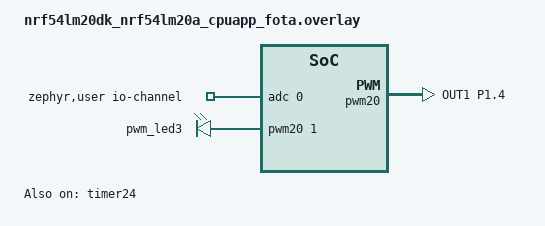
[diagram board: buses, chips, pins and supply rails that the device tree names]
/*
 * Copyright (c) 2026 Nordic Semiconductor ASA
 *
 * SPDX-License-Identifier: LicenseRef-Nordic-5-Clause
 */

#include <nrf54lm20_cpuapp_partitions.dtsi>
#include <ext_flash/nrf54lm20dk_cpuapp_partitions.dtsi>

/ {
	zephyr,user {
		io-channels = <&adc 0>;
	};

	chosen {
		ncs,zigbee-timer = &timer24;
	};

	pwmleds {
		compatible = "pwm-leds";
		pwm_led3: pwm_led_3 {
			pwms = <&pwm20 1 PWM_MSEC(20) PWM_POLARITY_INVERTED>;
		};
	};
};

&pwm20 {
	status = "okay";
	pinctrl-0 = <&pwm20_default>;
	pinctrl-1 = <&pwm20_sleep>;
	pinctrl-names = "default", "sleep";
};

&pinctrl {
	pwm20_default: pwm20_default {
		group1 {
			psels = <NRF_PSEL(PWM_OUT1, 1, 4)>;
		};
	};

	pwm20_sleep: pwm20_sleep {
		group1 {
			psels = <NRF_PSEL(PWM_OUT1, 1, 4)>;
			low-power-enable;
		};
	};
};

&timer24 {
	status = "okay";
};
